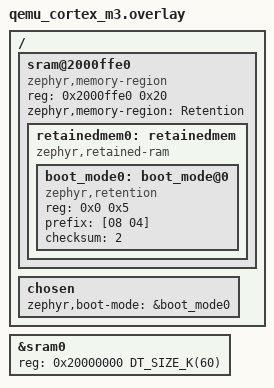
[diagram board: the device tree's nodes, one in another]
/*
 * Copyright (c) 2026 The Zephyr Project Contributors
 *
 * SPDX-License-Identifier: Apache-2.0
 */

#include <common/mem.h>

/ {
	sram@2000ffe0 {
		compatible = "zephyr,memory-region", "mmio-sram";
		reg = <0x2000ffe0 0x20>;
		ranges = <0x0 0x2000ffe0 0x20>;
		zephyr,memory-region = "Retention";
		status = "okay";
		#address-cells = <1>;
		#size-cells = <1>;

		retainedmem0: retainedmem {
			compatible = "zephyr,retained-ram";
			status = "okay";
			ranges;
			#address-cells = <1>;
			#size-cells = <1>;

			boot_mode0: boot_mode@0 {
				compatible = "zephyr,retention";
				status = "okay";
				reg = <0x0 0x5>;
				prefix = [08 04];
				checksum = <2>;
			};
		};
	};

	chosen {
		zephyr,boot-mode = &boot_mode0;
	};
};

&sram0 {
	reg = <0x20000000 DT_SIZE_K(60)>;
};
